# max3263x register map
Vendor: Maxim Integrated; Series: ARMCM4; File version: 1.1
CPU: CM4 r1p0, little endian, no MPU, FPU, 3 interrupt priority bits
Registers are 32-bit, read-write, reset 0x0 unless marked. A register's access mark holds for its fields unless they carry their own. Offsets are from the block's base; [hi:lo] are bit positions; {n}, {i} and the like mark numbered series.

## IOMAN — System I/O Manager
Base 0x40000C00
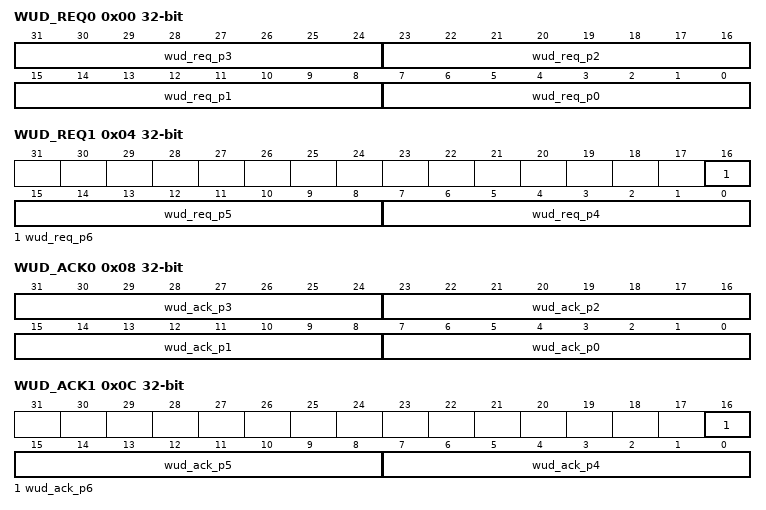
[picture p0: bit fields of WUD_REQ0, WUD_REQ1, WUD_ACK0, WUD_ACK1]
0x00 WUD_REQ0 — Wakeup Detect Mode Request Register 0 (P0/P1/P2/P3)
  [8n+7:8n] wud_req_p{n} (n=0..3) — Wakeup Detect Request Mode: P{n}[7:0]
0x04 WUD_REQ1 — Wakeup Detect Mode Request Register 1 (P4/P5/P6)
  [16] wud_req_p6 — Wakeup Detect Request Mode: P6[0]
  [15:8] wud_req_p5 — Wakeup Detect Request Mode: P5[7:0]
  [7:0] wud_req_p4 — Wakeup Detect Request Mode: P4[7:0]
0x08 WUD_ACK0 — Wakeup Detect Mode Acknowledge Register 0 (P0/P1/P2/P3)
  [8n+7:8n] wud_ack_p{n} ro (n=0..3) — WUD Mode Acknowledge: P{n}[7:0]
0x0C WUD_ACK1 — Wakeup Detect Mode Acknowledge Register 1 (P4/P5/P6)
  [16] wud_ack_p6 ro — WUD Mode Acknowledge: P6[7:0]
  [15:8] wud_ack_p5 ro — WUD Mode Acknowledge: P5[7:0]
  [7:0] wud_ack_p4 ro — WUD Mode Acknowledge: P4[7:0]
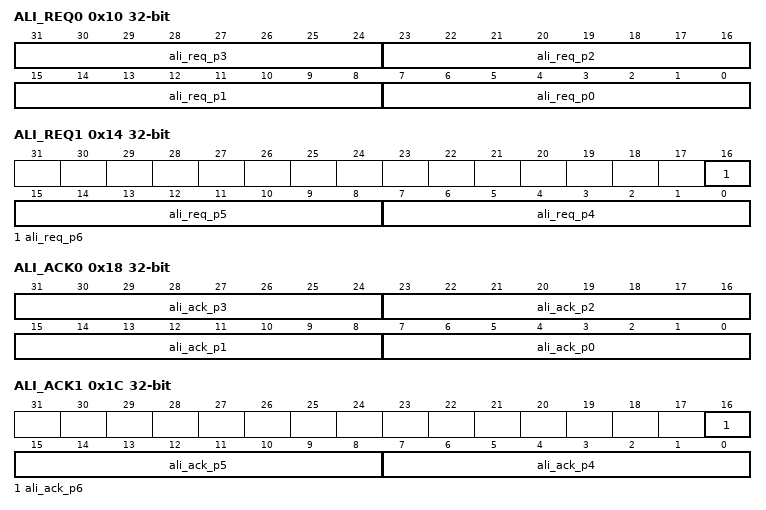
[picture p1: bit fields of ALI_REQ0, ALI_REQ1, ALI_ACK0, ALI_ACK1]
0x10 ALI_REQ0 — Analog Input Request Register 0 (P0/P1/P2/P3)
  [8n+7:8n] ali_req_p{n} (n=0..3) — Analog Input Mode Request: P{n}[7:0]
0x14 ALI_REQ1 — Analog Input Request Register 1 (P4/P5/P6)
  [16] ali_req_p6 — Analog Input Mode Request: P6[0]
  [15:8] ali_req_p5 — Analog Input Mode Request: P5[7:0]
  [7:0] ali_req_p4 — Analog Input Mode Request: P4[7:0]
0x18 ALI_ACK0 — Analog Input Acknowledge Register 0 (P0/P1/P2/P3)
  [8n+7:8n] ali_ack_p{n} ro (n=0..3) — Analog In Mode Acknowledge: P{n}[7:0]
0x1C ALI_ACK1 — Analog Input Acknowledge Register 1 (P4/P5/P6)
  [16] ali_ack_p6 ro — Analog In Mode Acknowledge: P6[0]
  [15:8] ali_ack_p5 ro — Analog In Mode Acknowledge: P5[7:0]
  [7:0] ali_ack_p4 ro — Analog In Mode Acknowledge: P4[7:0]
0x20 ALI_CONNECT0 — Analog I/O Connection Control Register 0
0x24 ALI_CONNECT1 — Analog I/O Connection Control Register 1
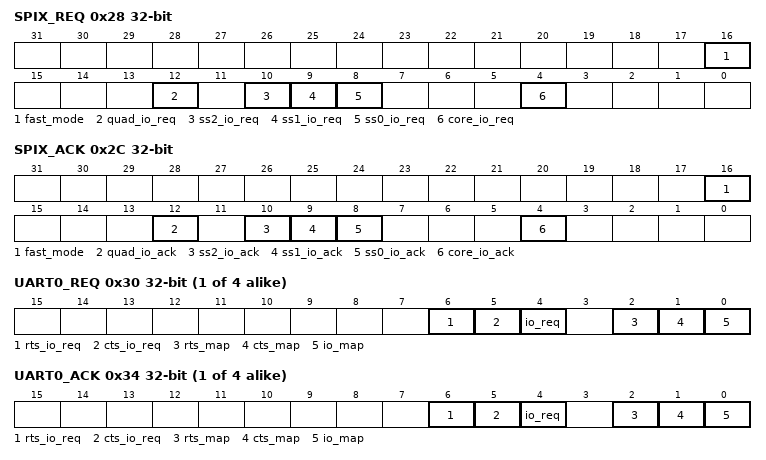
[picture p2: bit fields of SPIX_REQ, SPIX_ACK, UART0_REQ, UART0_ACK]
0x28 SPIX_REQ — SPIX I/O Mode Request
  [16] fast_mode — SPIX Fast Mode Request
  [12] quad_io_req — SPIX Quad I/O Request
  [10] ss2_io_req — SPIX SS[2] I/O Request
  [9] ss1_io_req — SPIX SS[1] I/O Request
  [8] ss0_io_req — SPIX SS[0] I/O Request
  [4] core_io_req — SPIX Core I/O Request
0x2C SPIX_ACK — SPIX I/O Mode Acknowledge
  [16] fast_mode ro — SPIX Fast Mode Acknowledge
  [12] quad_io_ack ro — SPIX Quad I/O Acknowledge
  [10] ss2_io_ack ro — SPIX SS[2] I/O Acknowledge
  [9] ss1_io_ack ro — SPIX SS[1] I/O Acknowledge
  [8] ss0_io_ack ro — SPIX SS[0] I/O Acknowledge
  [4] core_io_ack ro — SPIX Core I/O Acknowledge
{0x30+8i} UART{i}_REQ (i=0..3) — UART{i} I/O Mode Request
  [6] rts_io_req — UART{i} RTS I/O Request
  [5] cts_io_req — UART{i} CTS I/O Request
  [4] io_req — UART{i} TX/RX I/O Request
  [2] rts_map — UART{i} RTS I/O Mapping Select
  [1] cts_map — UART{i} CTS I/O Mapping Select
  [0] io_map — UART{i} TX/RX I/O Mapping Select
{0x34+8i} UART{i}_ACK (i=0..3) — UART{i} I/O Mode Acknowledge
  [6] rts_io_req ro — UART{i} RTS I/O Acknowledge
  [5] cts_io_req ro — UART{i} CTS I/O Acknowledge
  [4] io_req ro — UART{i} TX/RX I/O Acknowledge
  [2] rts_map ro — UART{i} RTS I/O Mapping Acknowledge
  [1] cts_map ro — UART{i} CTS I/O Mapping Acknowledge
  [0] io_map ro — UART{i} TX/RX I/O Mapping Acknowledge
{0x50+8i} I2CM{i}_REQ (i=0..2) — I2C Master {i} I/O Request
  [4] mapping_req
{0x54+8i} I2CM{i}_ACK (i=0..2) — I2C Master {i} I/O Acknowledge
  [4] mapping_ack ro
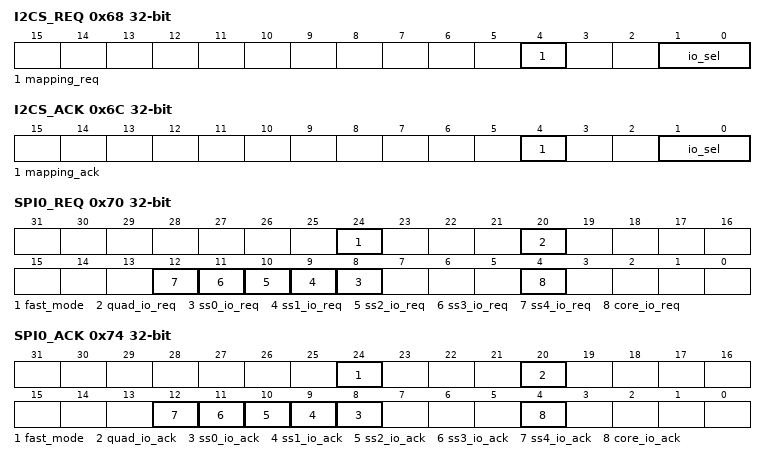
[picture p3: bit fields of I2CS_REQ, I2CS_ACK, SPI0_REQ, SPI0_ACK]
0x68 I2CS_REQ — I2C Slave I/O Request
  [4] mapping_req — I2C Slave I/O Request
  [1:0] io_sel — I2C Slave I/O Mapping Select
0x6C I2CS_ACK — I2C Slave I/O Acknowledge
  [4] mapping_ack ro — I2C Slave I/O Acknowledge
  [1:0] io_sel ro — I2C Slave I/O Mapping Acknowledge
0x70 SPI0_REQ — SPI Master 0 I/O Mode Request
  [24] fast_mode — SPI Master 0 Fast Mode Request
  [20] quad_io_req — SPI Master 0 Quad I/O Request
  [n+8] ss{n}_io_req (n=0..4) — SPI Master 0 SS[{n}] I/O Request
  [4] core_io_req — SPI Master 0 Core I/O Request
0x74 SPI0_ACK — SPI Master 0 I/O Mode Acknowledge
  [24] fast_mode ro — SPI Master 0 Fast Mode Acknowledge
  [20] quad_io_ack ro — SPI Master 0 Quad I/O Acknowledge
  [n+8] ss{n}_io_ack ro (n=0..4) — SPI Master 0 SS[{n}] I/O Acknowledge
  [4] core_io_ack ro — SPI Master 0 Core I/O Acknowledge
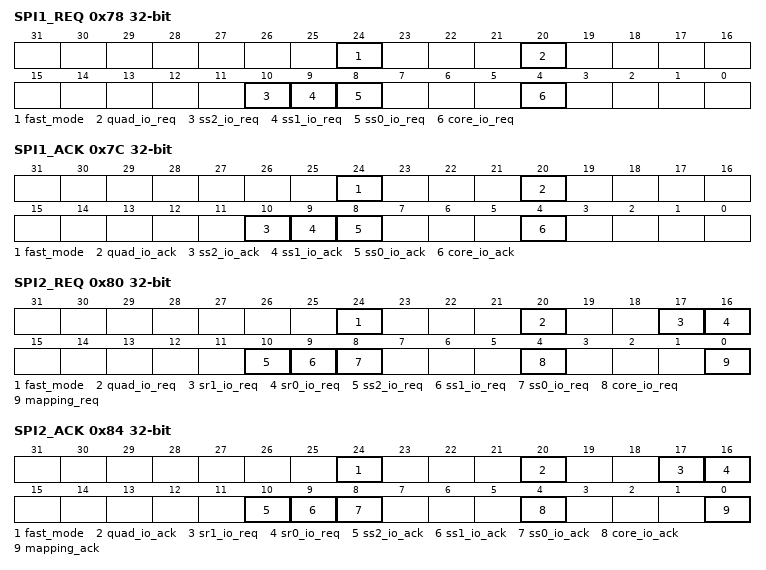
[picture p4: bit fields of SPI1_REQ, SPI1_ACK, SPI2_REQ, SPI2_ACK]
0x78 SPI1_REQ — SPI Master 1 I/O Mode Request
  [24] fast_mode — SPI Master 1 Fast Mode Request
  [20] quad_io_req — SPI Master 1 Quad I/O Request
  [10] ss2_io_req — SPI Master 1 SS[2] I/O Request
  [9] ss1_io_req — SPI Master 1 SS[1] I/O Request
  [8] ss0_io_req — SPI Master 1 SS[0] I/O Request
  [4] core_io_req — SPI Master 1 Core I/O Request
0x7C SPI1_ACK — SPI Master 1 I/O Mode Acknowledge
  [24] fast_mode ro — SPI Master 1 Fast Mode Acknowledge
  [20] quad_io_ack ro — SPI Master 1 Quad I/O Acknowledge
  [10] ss2_io_ack ro — SPI Master 1 SS[2] I/O Acknowledge
  [9] ss1_io_ack ro — SPI Master 1 SS[1] I/O Acknowledge
  [8] ss0_io_ack ro — SPI Master 1 SS[0] I/O Acknowledge
  [4] core_io_ack ro — SPI Master 1 Core I/O Acknowledge
0x80 SPI2_REQ — SPI Master 2 I/O Mode Request
  [24] fast_mode — SPI Master 2 Fast Mode Request
  [20] quad_io_req — SPI Master 2 Quad I/O Request
  [17] sr1_io_req — SPI Master 2 SR[1] I/O Request
  [16] sr0_io_req — SPI Master 2 SR[0] I/O Request
  [10] ss2_io_req — SPI Master 2 SS[2] I/O Request
  [9] ss1_io_req — SPI Master 2 SS[1] I/O Request
  [8] ss0_io_req — SPI Master 2 SS[0] I/O Request
  [4] core_io_req — SPI Master 2 Core I/O Request
  [0] mapping_req — SPI Master 2 I/O Mapping Select
0x84 SPI2_ACK — SPI Master 2 I/O Mode Acknowledge
  [24] fast_mode ro — SPI Master 2 Fast Mode Acknowledge
  [20] quad_io_ack ro — SPI Master 2 Quad I/O Acknowledge
  [17] sr1_io_req ro — SPI Master 2 SR[1] I/O Acknowledge
  [16] sr0_io_req ro — SPI Master 2 SR[0] I/O Acknowledge
  [10] ss2_io_ack ro — SPI Master 2 SS[2] I/O Acknowledge
  [9] ss1_io_ack ro — SPI Master 2 SS[1] I/O Acknowledge
  [8] ss0_io_ack ro — SPI Master 2 SS[0] I/O Acknowledge
  [4] core_io_ack ro — SPI Master 2 Core I/O Acknowledge
  [0] mapping_ack ro — SPI Master 2 I/O Mapping Acknowledge
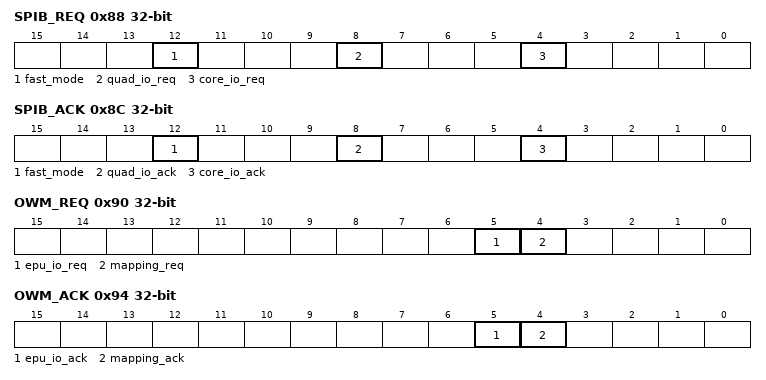
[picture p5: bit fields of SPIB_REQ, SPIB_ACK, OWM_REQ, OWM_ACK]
0x88 SPIB_REQ — SPI Bridge I/O Mode Request
  [12] fast_mode ro — SPI Bridge Fast Mode Request
  [8] quad_io_req ro — SPI Bridge Quad I/O Request
  [4] core_io_req ro — SPI Bridge Core I/O Request
0x8C SPIB_ACK — SPI Bridge I/O Mode Acknowledge
  [12] fast_mode ro — SPI Bridge Fast Mode Acknowledge
  [8] quad_io_ack ro — SPI Bridge Quad I/O Acknowledge
  [4] core_io_ack ro — SPI Bridge Core I/O Acknowledge
0x90 OWM_REQ — 1-Wire Master I/O Mode Request
  [5] epu_io_req — External Pullup Control Line I/O Request
  [4] mapping_req — 1-Wire Line I/O Request
0x94 OWM_ACK — 1-Wire Master I/O Mode Acknowledge
  [5] epu_io_ack — External Pullup Control Line I/O Acknowledge
  [4] mapping_ack — 1-Wire Line I/O Acknowledge
